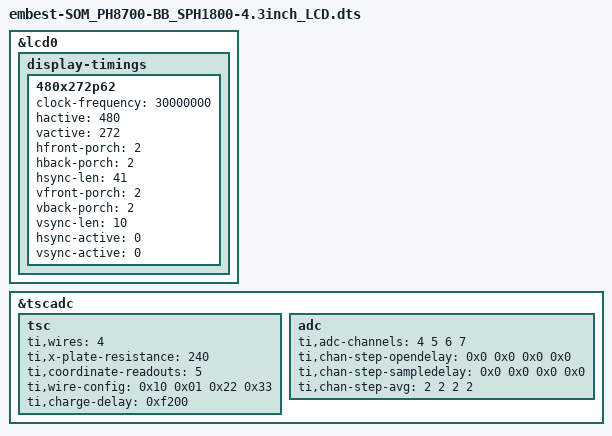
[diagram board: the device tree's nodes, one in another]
/*
 * Copyright (C) 2015 Embest Technology Co., Ltd., - http://www.embest-tech.com
 *
 * This program is free software; you can redistribute it and/or modify
 * it under the terms of the GNU General Public License version 2 as
 * published by the Free Software Foundation.
 *
 * This dts is for embest own product:
 * SOM-PH8700 + BB-SPH1800
 */
/*/dts-v1/;*/

#include "embest-SOM_PH8700-BB_SPH1800.dts"

&lcd0 {
	display-timings {
		480x272p62 {
			clock-frequency = <30000000>;
			hactive = <480>;
			vactive = <272>;
			hfront-porch = <2>;
			hback-porch = <2>;
			hsync-len = <41>;
			vfront-porch = <2>;
			vback-porch = <2>;
			vsync-len = <10>;
			hsync-active = <0>;
			vsync-active = <0>;
		};
	};
};

&tscadc {
	status = "okay";

	tsc {
		ti,wires = <4>;
		ti,x-plate-resistance = <240>;
		ti,coordinate-readouts = <5>;
		ti,wire-config = <0x10 0x01 0x22 0x33>;
		ti,charge-delay = <0xf200>;
	};

	adc { 
		ti,adc-channels = <4 5 6 7>;
		ti,chan-step-opendelay = <0x0 0x0 0x0 0x0>;
		ti,chan-step-sampledelay = <0x0 0x0 0x0 0x0>;
		ti,chan-step-avg = <2 2 2 2>; 
	};
};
